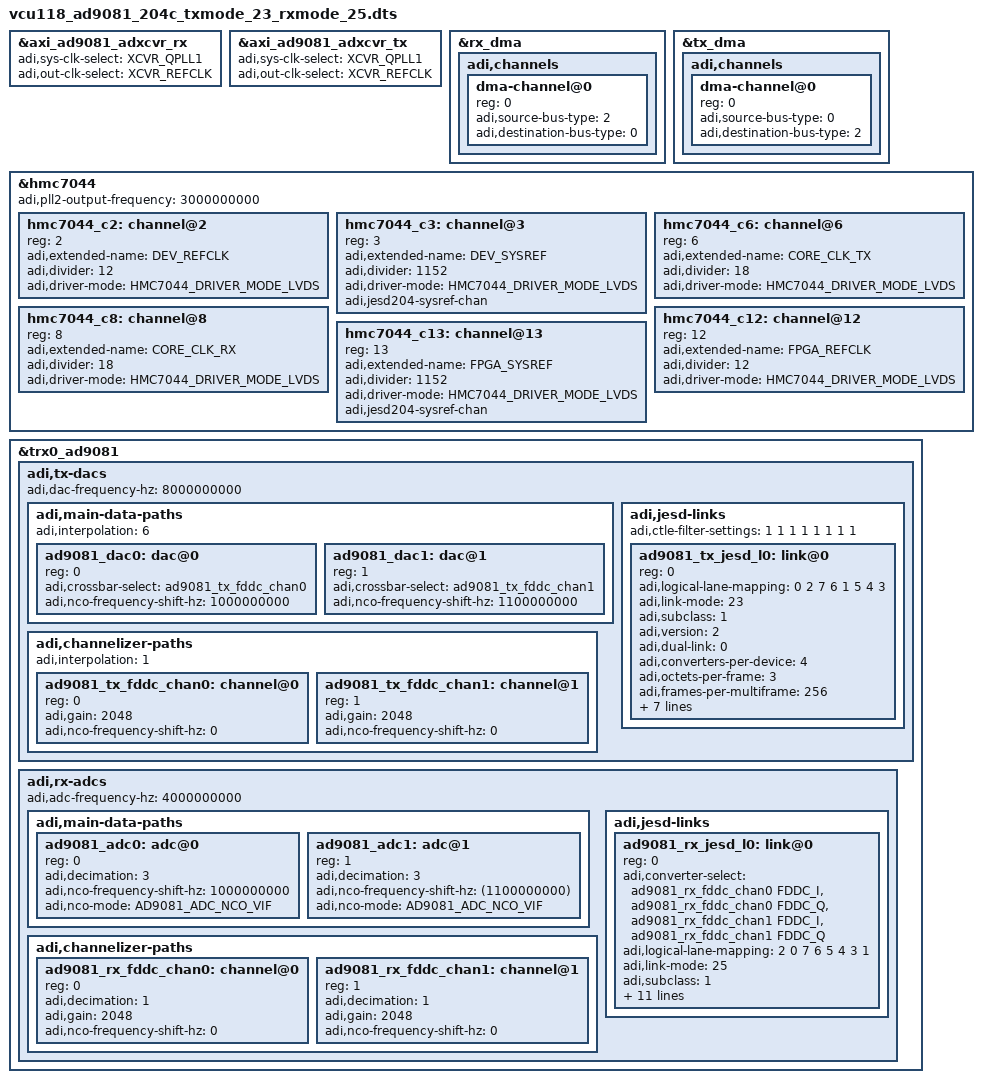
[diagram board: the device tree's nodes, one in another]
// SPDX-License-Identifier: GPL-2.0
/*
 * Analog Devices AD9081-FMC-EBZ
 * https://wiki.analog.com/resources/tools-software/linux-drivers/iio-mxfe/ad9081
 * https://wiki.analog.com/resources/eval/user-guides/ad9081_fmca_ebz/ad9081_fmca_ebz_hdl
 *
 * hdl_project: <ad9081_fmca_ebz/vcu118>
 * board_revision: <>
 *
 * Copyright (C) 2019-2020 Analog Devices Inc.
 */

/*
 *	Lane Rate = 16.5 Gpbs
 *	Link Clock = 250 MHz
 */

#include "vcu118_ad9081.dts"

&axi_ad9081_adxcvr_rx {
	adi,sys-clk-select = <XCVR_QPLL1>;
	adi,out-clk-select = <XCVR_REFCLK>;
};

&axi_ad9081_adxcvr_tx {
	adi,sys-clk-select = <XCVR_QPLL1>;
	adi,out-clk-select = <XCVR_REFCLK>;
};

&rx_dma {
	adi,channels {
		dma-channel@0 {
			reg = <0>;
			adi,source-bus-type = <2>;
			adi,destination-bus-type = <0>;
		};
	};
};

&tx_dma {
	adi,channels {
		dma-channel@0 {
			reg = <0>;
			adi,source-bus-type = <0>;
			adi,destination-bus-type = <2>;
		};
	};
};

&hmc7044 {

	adi,pll2-output-frequency = <3000000000>;

		hmc7044_c2: channel@2 {
			reg = <2>;
			adi,extended-name = "DEV_REFCLK";
			adi,divider = <12>;	// 250
			adi,driver-mode = <HMC7044_DRIVER_MODE_LVDS>;	// LVDS
		};

		hmc7044_c3: channel@3 {
			reg = <3>;
			adi,extended-name = "DEV_SYSREF";
			adi,divider = <1152>;	//
			adi,driver-mode = <HMC7044_DRIVER_MODE_LVDS>;	// LVDS
			adi,jesd204-sysref-chan;
		};

		hmc7044_c6: channel@6 {
			reg = <6>;
			adi,extended-name = "CORE_CLK_TX";
			adi,divider = <18>;	// 166.66
			adi,driver-mode = <HMC7044_DRIVER_MODE_LVDS>;	// LVDS
		};

		hmc7044_c8: channel@8 {
			reg = <8>;
			adi,extended-name = "CORE_CLK_RX";
			adi,divider = <18>;	// 166.66
			adi,driver-mode = <HMC7044_DRIVER_MODE_LVDS>;	// LVDS
		};


		hmc7044_c12: channel@12 {
			reg = <12>;
			adi,extended-name = "FPGA_REFCLK";
			adi,divider = <12>;	// 250
			adi,driver-mode = <HMC7044_DRIVER_MODE_LVDS>;	// LVDS
		};

		hmc7044_c13: channel@13 {
			reg = <13>;
			adi,extended-name = "FPGA_SYSREF";
			adi,divider = <1152>;	//
			adi,driver-mode = <HMC7044_DRIVER_MODE_LVDS>;	// LVDS
			adi,jesd204-sysref-chan;
		};

};

&trx0_ad9081 {
	adi,tx-dacs {
		#size-cells = <0>;
		#address-cells = <1>;
		adi,dac-frequency-hz = /bits/ 64 <8000000000>;
		adi,main-data-paths {
			#address-cells = <1>;
			#size-cells = <0>;
			adi,interpolation = <6>;
			ad9081_dac0: dac@0 {
				reg = <0>;
				adi,crossbar-select = <&ad9081_tx_fddc_chan0>;
				adi,nco-frequency-shift-hz = /bits/ 64 <1000000000>; /* 1000 MHz */
			};
			ad9081_dac1: dac@1 {
				reg = <1>;
				adi,crossbar-select = <&ad9081_tx_fddc_chan1>;
				adi,nco-frequency-shift-hz = /bits/ 64 <1100000000>; /* 1100 MHz */
			};
		};

		adi,channelizer-paths {
			#address-cells = <1>;
			#size-cells = <0>;
			adi,interpolation = <1>;
			ad9081_tx_fddc_chan0: channel@0 {
				reg = <0>;
				adi,gain = <2048>; /* 2048 * 10^(gain_dB/20) */
				adi,nco-frequency-shift-hz =  /bits/ 64 <0>;
			};
			ad9081_tx_fddc_chan1: channel@1 {
				reg = <1>;
				adi,gain = <2048>; /* 2048 * 10^(gain_dB/20) */
				adi,nco-frequency-shift-hz =  /bits/ 64 <0>;
			};
		};

		adi,jesd-links {
			#size-cells = <0>;
			#address-cells = <1>;

			adi,ctle-filter-settings = /bits/ 8 <1 1 1 1 1 1 1 1>;

			ad9081_tx_jesd_l0: link@0 {
				#address-cells = <1>;
				#size-cells = <0>;
				reg = <0>;
				adi,logical-lane-mapping = /bits/ 8 <0 2 7 6 1 5 4 3>;
				adi,link-mode = <23>;			/* JESD Quick Configuration Mode */
				adi,subclass = <1>;			/* JESD SUBCLASS 0,1,2 */
				adi,version = <2>;			/* JESD VERSION 0=204A,1=204B,2=204C */
				adi,dual-link = <0>;			/* JESD Dual Link Mode */
				adi,converters-per-device = <4>;	/* JESD M */
				adi,octets-per-frame = <3>;		/* JESD F */
				adi,frames-per-multiframe = <256>;	/* JESD K */
				adi,converter-resolution = <12>;	/* JESD N */
				adi,bits-per-sample = <12>;		/* JESD NP' */
				adi,control-bits-per-sample = <0>;	/* JESD CS */
				adi,lanes-per-device = <4>;		/* JESD L */
				adi,samples-per-converter-per-frame = <2>; /* JESD S */
				adi,high-density = <1>;			/* JESD HD */

				adi,tpl-phase-adjust = <0x3c>;
			};
		};
	};
	adi,rx-adcs {
		#size-cells = <0>;
		#address-cells = <1>;
		adi,adc-frequency-hz = /bits/ 64 <4000000000>;
		adi,main-data-paths {
			#address-cells = <1>;
			#size-cells = <0>;
			ad9081_adc0: adc@0 {
				reg = <0>;
				adi,decimation = <3>;
				adi,nco-frequency-shift-hz =  /bits/ 64 <1000000000>;
				adi,nco-mode = <AD9081_ADC_NCO_VIF>;
			};
			ad9081_adc1: adc@1 {
				reg = <1>;
				adi,decimation = <3>;
				adi,nco-frequency-shift-hz =  /bits/ 64 <(1100000000)>;
				adi,nco-mode = <AD9081_ADC_NCO_VIF>;
			};
		};
		adi,channelizer-paths {
			#address-cells = <1>;
			#size-cells = <0>;
			ad9081_rx_fddc_chan0: channel@0 {
				reg = <0>;
				adi,decimation = <1>;
				adi,gain = <2048>; /* 2048 * 10^(gain_dB/20) */
				adi,nco-frequency-shift-hz =  /bits/ 64 <0>;
			};
			ad9081_rx_fddc_chan1: channel@1 {
				reg = <1>;
				adi,decimation = <1>;
				adi,gain = <2048>; /* 2048 * 10^(gain_dB/20) */
				adi,nco-frequency-shift-hz =  /bits/ 64 <0>;
			};
		};
		adi,jesd-links {
			#size-cells = <0>;
			#address-cells = <1>;
			ad9081_rx_jesd_l0: link@0 {
				reg = <0>;
				adi,converter-select =
					<&ad9081_rx_fddc_chan0 FDDC_I>, <&ad9081_rx_fddc_chan0 FDDC_Q>,
					<&ad9081_rx_fddc_chan1 FDDC_I>, <&ad9081_rx_fddc_chan1 FDDC_Q>;
				adi,logical-lane-mapping = /bits/ 8 <2 0 7 6 5 4 3 1>;
				adi,link-mode = <25>;			/* JESD Quick Configuration Mode */
				adi,subclass = <1>;			/* JESD SUBCLASS 0,1,2 */
				adi,version = <2>;			/* JESD VERSION 0=204A,1=204B,2=204C */
				adi,dual-link = <0>;			/* JESD Dual Link Mode */
				adi,converters-per-device = <4>;	/* JESD M */
				adi,octets-per-frame = <3>;		/* JESD F */
				adi,frames-per-multiframe = <256>;	/* JESD K */
				adi,converter-resolution = <12>;	/* JESD N */
				adi,bits-per-sample = <12>;		/* JESD NP' */
				adi,control-bits-per-sample = <0>;	/* JESD CS */
				adi,lanes-per-device = <4>;		/* JESD L */
				adi,samples-per-converter-per-frame = <2>; /* JESD S */
				adi,high-density = <1>;			/* JESD HD */
			};
		};
	};
};

